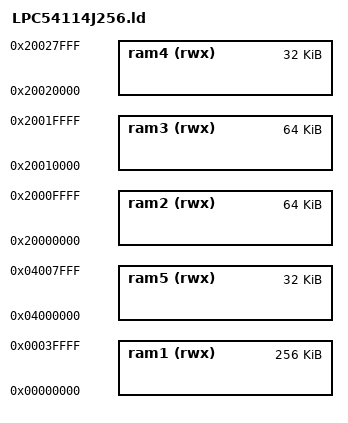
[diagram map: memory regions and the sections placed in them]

MEMORY
{
  ram1 (rwx) : ORIGIN = 0x00000000, LENGTH = 0x040000
  ram2 (rwx) : ORIGIN = 0x20000000, LENGTH = 0x010000
  ram3 (rwx) : ORIGIN = 0x20010000, LENGTH = 0x010000
  ram4 (rwx) : ORIGIN = 0x20020000, LENGTH = 0x8000
  ram5 (rwx) : ORIGIN = 0x04000000, LENGTH = 0x8000
}

